# S6E2D5 register map
File version: 1.1
CPU: CM4 r0p1, little endian, MPU, FPU, 4 interrupt priority bits
Registers are 32-bit, read-write, reset 0x0 unless marked. A register's access mark holds for its fields unless they carry their own. Offsets are from the block's base; [hi:lo] are bit positions; {n}, {i} and the like mark numbered series; 'fields as' and 'values as' point back to an identical list.

## EXBUS — External Bus Interface
Base 0x4003F000
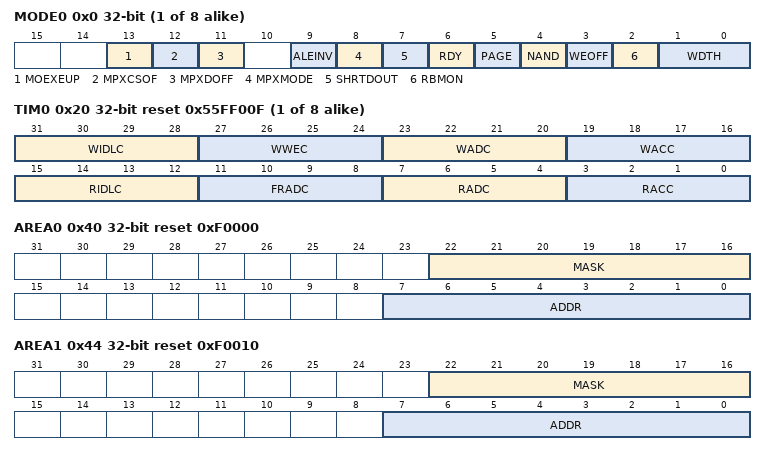
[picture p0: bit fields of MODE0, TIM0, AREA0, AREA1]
{0x0+4i} MODE{i} (i=0..7) — Mode Register {i}
  [13] MOEXEUP — select how to set the MOEX width
  [12] MPXCSOF — select a CS assertion from the start of accessing to the end of address output
  [11] MPXDOFF — select whether or not the address is output to the data lines in multiplex mode
  [9] ALEINV — set up the polarity of the ALE signal
  [8] MPXMODE — select operation bus mode
  [7] SHRTDOUT — select to which idle cycle the write data output is extended
  [6] RDY — control the external RDY function
  [5] PAGE — NOR Flash memory page access mode
  [4] NAND — NAND Flash memory mode
  [3] WEOFF — disable the write enable signal (MWEX) operation
  [2] RBMON — Read Byte Mask ON
  [1:0] WDTH — specify Data Width
{0x20+4i} TIM{i} reset 0x55FF00F (i=0..7) — Timing Register {i}
  [31:28] WIDLC — Write Idle Cycle
  [27:24] WWEC — Write Enable Cycle
  [23:20] WADC — Write Address Setup cycle
  [19:16] WACC — Write Access Cycle
  [15:12] RIDLC — Read Idle Cycle
  [11:8] FRADC — First Read Address Cycle
  [7:4] RADC — Read Address Setup cycle
  [3:0] RACC — Read Access Cycle
0x40 AREA0 reset 0xF0000 — Area Register 0
  [22:16] MASK — address mask
  [7:0] ADDR — Address
0x44 AREA1 reset 0xF0010 — Area Register 1
  [22:16] MASK — address mask
  [7:0] ADDR — Address
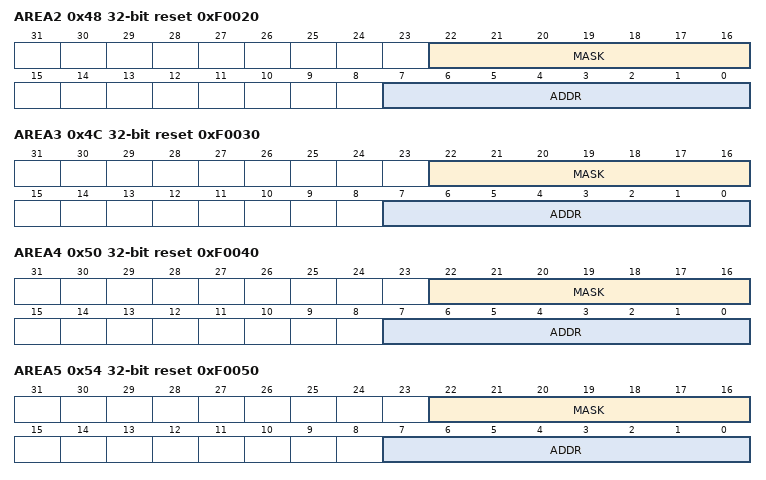
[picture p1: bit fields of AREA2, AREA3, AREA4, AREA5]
0x48 AREA2 reset 0xF0020 — Area Register 2
  [22:16] MASK — address mask
  [7:0] ADDR — Address
0x4C AREA3 reset 0xF0030 — Area Register 3
  [22:16] MASK — address mask
  [7:0] ADDR — Address
0x50 AREA4 reset 0xF0040 — Area Register 4
  [22:16] MASK — address mask
  [7:0] ADDR — Address
0x54 AREA5 reset 0xF0050 — Area Register 5
  [22:16] MASK — address mask
  [7:0] ADDR — Address
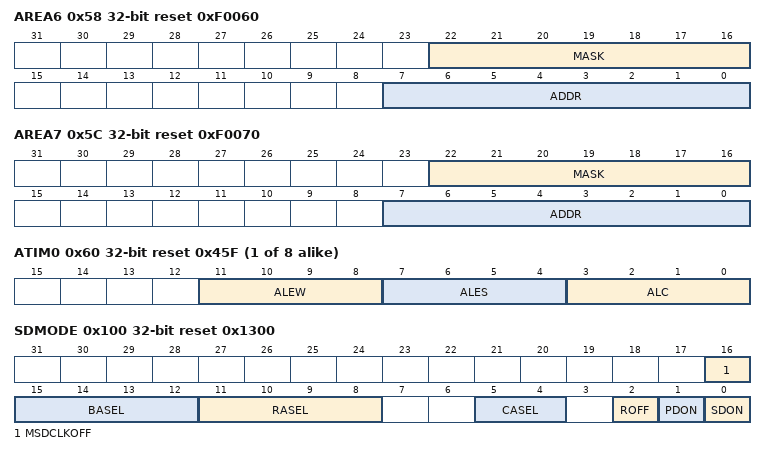
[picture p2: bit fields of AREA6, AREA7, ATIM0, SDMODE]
0x58 AREA6 reset 0xF0060 — Area Register 6
  [22:16] MASK — address mask
  [7:0] ADDR — Address
0x5C AREA7 reset 0xF0070 — Area Register 7
  [22:16] MASK — address mask
  [7:0] ADDR — Address
{0x60+4i} ATIM{i} reset 0x45F (i=0..7) — ALE Timing Register {i}
  [11:8] ALEW — Address Latch Enable Width
  [7:4] ALES — Address Latch Enable Setup cycle
  [3:0] ALC — Address Latch Cycle
0x100 SDMODE reset 0x1300 — SDRAM Mode Register
  [16] MSDCLKOFF
  [15:12] BASEL — Bank Address Select
  [11:8] RASEL — Row Address Select
  [5:4] CASEL — Column Address Select
  [2] ROFF — Refresh OFF
  [1] PDON — Power Down ON
  [0] SDON — SDRAM ON
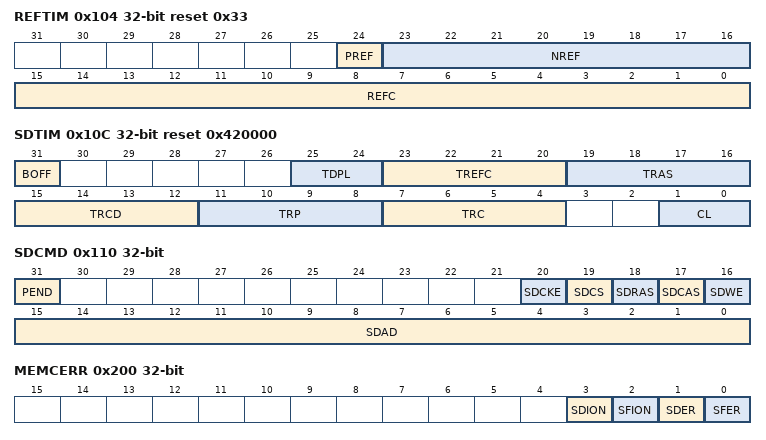
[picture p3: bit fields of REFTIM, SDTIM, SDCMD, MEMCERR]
0x104 REFTIM reset 0x33 — Refresh Timer Register
  [24] PREF — Pre-Refresh
  [23:16] NREF — Number of Refresh
  [15:0] REFC — Refresh Count
0x108 PWRDWN — Power Down Count Register
  [15:0] PDC — Power Down Count
0x10C SDTIM reset 0x420000 — SDRAM Timing Register
  [31] BOFF — Buffer readout bit
  [25:24] TDPL — Data-in to Precharge Lead Time
  [23:20] TREFC — Refresh Cycle time
  [19:16] TRAS — RAS active time
  [15:12] TRCD — RAS-CAS Delay
  [11:8] TRP — RAS Precharge time
  [7:4] TRC — RAS Cycle time
  [1:0] CL — CAS Latency
0x110 SDCMD — SDRAM Command Register
  [31] PEND ro
  [20] SDCKE — SDRAM CKE
  [19] SDCS — SDRAM Chip Select
  [18] SDRAS — SDRAM RAS
  [17] SDCAS — SDRAM CAS
  [16] SDWE — SDRAM Write Enable
  [15:0] SDAD — SDRAM ADress
0x200 MEMCERR — Memory Controller Register
  [3] SDION — SDRAM error Interrupt ON
  [2] SFION — SRAM/Flash error Interrupt ON
  [1] SDER — SDRAM Error
  [0] SFER — SRAM/Flash Error
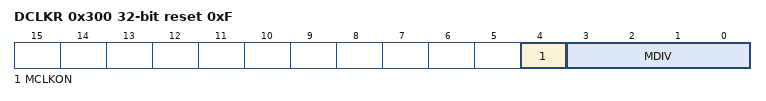
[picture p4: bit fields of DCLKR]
0x300 DCLKR reset 0xF — Division Clock Register
  [4] MCLKON
  [3:0] MDIV — MCLK Division Ratio Setup
0x304 EST ro — Error Status Register
  [0] WERR
0x308 WEAD ro — Write Error Address Register
  [31:0] ADDR
0x30C ESCLR wo reset 0x1 — Error Status Clear Register
  [0] WERRCLR — Write Error Clear
0x310 AMODE reset 0x1 — Access Mode Register
  [0] WAEN

## SDRAMC — GDC Sub system SDRAM Controller
Base 0xD0A03000
Registers as EXBUS, without MODE{n} (n=0..7), TIM{n} (n=0..7), AREA{n} (n=0..7), ATIM{n} (n=0..7), MEMCERR, DCLKR, EST, WEAD, ESCLR, AMODE; these are added or differ:
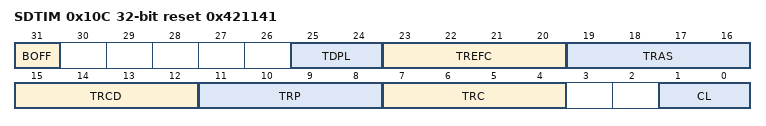
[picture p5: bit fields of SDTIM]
0x10C SDTIM reset 0x421141 — SDRAM Timing Register
  fields as EXBUS.SDTIM
